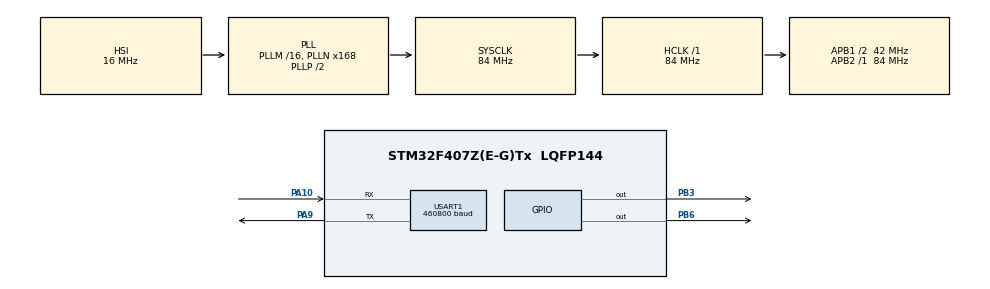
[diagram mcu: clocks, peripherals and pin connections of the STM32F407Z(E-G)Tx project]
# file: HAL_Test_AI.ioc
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Dma.Request0=USART1_TX
Dma.USART1_TX.0.Direction=DMA_MEMORY_TO_PERIPH
Dma.USART1_TX.0.FIFOMode=DMA_FIFOMODE_DISABLE
Dma.USART1_TX.0.Instance=DMA2_Stream7
Dma.USART1_TX.0.MemDataAlignment=DMA_MDATAALIGN_BYTE
Dma.USART1_TX.0.MemInc=DMA_MINC_ENABLE
Dma.USART1_TX.0.Mode=DMA_NORMAL
Dma.USART1_TX.0.PeriphDataAlignment=DMA_PDATAALIGN_BYTE
Dma.USART1_TX.0.PeriphInc=DMA_PINC_DISABLE
Dma.USART1_TX.0.Priority=DMA_PRIORITY_MEDIUM
Mcu.Family=STM32F4
Mcu.Name=STM32F407Z(E-G)Tx
Mcu.Package=LQFP144
NVIC.DMA2_Stream7_IRQn=true\:0\:0\:false\:false\:true\:false\:true\:true
NVIC.PriorityGroup=NVIC_PRIORITYGROUP_4
NVIC.TIM1_UP_TIM10_IRQn=true\:1\:0\:true\:false\:true\:true\:true\:true
NVIC.USART1_IRQn=true\:2\:0\:true\:false\:true\:false\:true\:true
PA10.Mode=Asynchronous
PA10.Signal=USART1_RX
PA13.Mode=Serial_Wire
PA13.Signal=SYS_JTMS-SWDIO
PA14.Mode=Serial_Wire
PA14.Signal=SYS_JTCK-SWCLK
PA9.Mode=Asynchronous
PA9.Signal=USART1_TX
PB3.GPIO_ModeDefaultOutputPP=GPIO_MODE_OUTPUT_OD
PB3.GPIO_PuPd=GPIO_PULLUP
PB3.GPIO_Speed=GPIO_SPEED_FREQ_HIGH
PB3.PinState=GPIO_PIN_SET
PB3.Signal=GPIO_Output
PB6.GPIO_ModeDefaultOutputPP=GPIO_MODE_OUTPUT_OD
PB6.GPIO_PuPd=GPIO_PULLUP
PB6.GPIO_Speed=GPIO_SPEED_FREQ_HIGH
PB6.PinState=GPIO_PIN_SET
PB6.Signal=GPIO_Output
PH0-OSC_IN.Mode=HSE-External-Clock-Source
PH0-OSC_IN.Signal=RCC_OSC_IN
PH1-OSC_OUT.Mode=HSE-External-Clock-Source
PH1-OSC_OUT.Signal=RCC_OSC_OUT
ProjectManager.HeapSize=0x200
ProjectManager.StackSize=0x400
ProjectManager.TargetToolchain=MDK-ARM V5.32
RCC.48MHZClocksFreq_Value=42000000
RCC.AHBFreq_Value=84000000
RCC.APB1CLKDivider=RCC_HCLK_DIV2
RCC.APB1Freq_Value=42000000
RCC.APB1TimFreq_Value=84000000
RCC.APB2Freq_Value=84000000
RCC.APB2TimFreq_Value=84000000
RCC.CortexFreq_Value=84000000
RCC.HCLKFreq_Value=84000000
RCC.HSE_VALUE=25000000
RCC.HSI_VALUE=16000000
RCC.LSE_VALUE=32768
RCC.PLLN=168
RCC.SYSCLKFreq_VALUE=84000000
RCC.SYSCLKSource=RCC_SYSCLKSOURCE_PLLCLK
RCC.VCOOutputFreq_Value=168000000
TIM1.Period=999
TIM1.Prescaler=83
TIM1.RepetitionCounter=9
USART1.BaudRate=460800
USART1.VirtualMode=VM_ASYNC
VP_TIM1_VS_ClockSourceINT.Mode=Internal
board=custom

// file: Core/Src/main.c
/* USER CODE BEGIN Header */
/**
  ******************************************************************************
  * @file           : main.c
  * @brief          : Main program body
  ******************************************************************************
  * @attention
  *
  * Copyright (c) 2025 STMicroelectronics.
  * All rights reserved.
  *
  * This software is licensed under terms that can be found in the LICENSE file
  * in the root directory of this software component.
  * If no LICENSE file comes with this software, it is provided AS-IS.
  *
  ******************************************************************************
  */
/* USER CODE END Header */
#include "main.h"
#include "dma.h"
#include "tim.h"
#include "usart.h"
#include "gpio.h"

/* USER CODE BEGIN Includes */
#include "bsp_tim.h"
#include "bsp_soft_i2c.h"
#include "bsp_usart.h"
/* USER CODE END Includes */

/* USER CODE BEGIN PV */
uint8_t fifo_buffer[6] = {0};
uint8_t reg_commands[] = {0x04, 0x05, 0x06, 0x08, 0x0A, 0x0C, 0x0D, 0x09};
uint8_t commands[] = {0x00, 0x00, 0x00, 0x00, 0x77, 0xEF, 0xEF, 0x03};
/* USER CODE END PV */

void SystemClock_Config(void);

int main(void)
{

  /* MCU Configuration--------------------------------------------------------*/

  /* Reset of all peripherals, Initializes the Flash interface and the Systick. */
  HAL_Init();

  /* Configure the system clock */
  SystemClock_Config();

  /* Initialize all configured peripherals */
  MX_GPIO_Init();
  MX_DMA_Init();
  MX_TIM1_Init();
  MX_USART1_UART_Init();
  /* USER CODE BEGIN 2 */
  /*启动updata中断*/
  HAL_TIM_Base_Start_IT(&htim1);

  /*初始化max30102*/
  HR_Device_Init(0x57, reg_commands, commands, 8);
  /* USER CODE END 2 */

  /* Infinite loop */
  while (1)
  {

		}
}

void SystemClock_Config(void)
{
  RCC_OscInitTypeDef RCC_OscInitStruct = {0};
  RCC_ClkInitTypeDef RCC_ClkInitStruct = {0};

  /** Configure the main internal regulator output voltage
  */
  __HAL_RCC_PWR_CLK_ENABLE();
  __HAL_PWR_VOLTAGESCALING_CONFIG(PWR_REGULATOR_VOLTAGE_SCALE1);

  /** Initializes the RCC Oscillators according to the specified parameters
  * in the RCC_OscInitTypeDef structure.
  */
  RCC_OscInitStruct.OscillatorType = RCC_OSCILLATORTYPE_HSI;
  RCC_OscInitStruct.HSIState = RCC_HSI_ON;
  RCC_OscInitStruct.HSICalibrationValue = RCC_HSICALIBRATION_DEFAULT;
  RCC_OscInitStruct.PLL.PLLState = RCC_PLL_ON;
  RCC_OscInitStruct.PLL.PLLSource = RCC_PLLSOURCE_HSI;
  RCC_OscInitStruct.PLL.PLLM = 16;
  RCC_OscInitStruct.PLL.PLLN = 168;
  RCC_OscInitStruct.PLL.PLLP = RCC_PLLP_DIV2;
  RCC_OscInitStruct.PLL.PLLQ = 4;
  if (HAL_RCC_OscConfig(&RCC_OscInitStruct) != HAL_OK)
  {
    Error_Handler();
  }

  /** Initializes the CPU, AHB and APB buses clocks
  */
  RCC_ClkInitStruct.ClockType = RCC_CLOCKTYPE_HCLK|RCC_CLOCKTYPE_SYSCLK
                              |RCC_CLOCKTYPE_PCLK1|RCC_CLOCKTYPE_PCLK2;
  RCC_ClkInitStruct.SYSCLKSource = RCC_SYSCLKSOURCE_PLLCLK;
  RCC_ClkInitStruct.AHBCLKDivider = RCC_SYSCLK_DIV1;
  RCC_ClkInitStruct.APB1CLKDivider = RCC_HCLK_DIV2;
  RCC_ClkInitStruct.APB2CLKDivider = RCC_HCLK_DIV1;

  if (HAL_RCC_ClockConfig(&RCC_ClkInitStruct, FLASH_LATENCY_2) != HAL_OK)
  {
    Error_Handler();
  }
}

void Error_Handler(void)
{
  __disable_irq();
  while (1)
  {
  }
}
